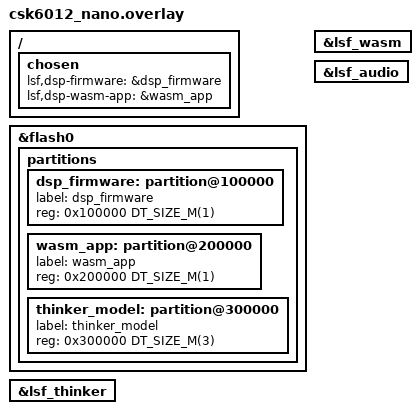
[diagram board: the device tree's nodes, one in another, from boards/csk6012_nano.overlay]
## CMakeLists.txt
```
# Copyright (c) 2023 LISTENAI
# SPDX-License-Identifier: Apache-2.0

cmake_minimum_required(VERSION 3.20.0)

find_package(Zephyr REQUIRED HINTS $ENV{ZEPHYR_BASE})
project(thinker_wasm_test)

target_sources(app PRIVATE src/main.c)
```

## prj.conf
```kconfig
CONFIG_HEAP_MEM_POOL_SIZE=204800

CONFIG_CSK_HEAP=y
CONFIG_CSK_HEAP_MEM_POOL_SIZE=40960
CONFIG_ZTEST=y

CONFIG_CSK6_FLASH_STALL_SECOND_CORE=n
```

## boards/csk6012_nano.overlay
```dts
/*
 * Copyright(c) 2023 LISTENAI
 * SPDX-License-Identifier: Apache-2.0
 */

#include <lsf/lsf.dtsi>

/ {
	chosen {
		lsf,dsp-firmware = &dsp_firmware;
		lsf,dsp-wasm-app = &wasm_app;
	};
};

&flash0 {
	partitions {
		dsp_firmware: partition@100000 {
			label = "dsp_firmware";
			reg = <0x100000 DT_SIZE_M(1)>;
		};

		wasm_app: partition@200000 {
			label = "wasm_app";
			reg = <0x200000 DT_SIZE_M(1)>;
		};

		thinker_model: partition@300000 {
			label = "thinker_model";
			reg = <0x300000 DT_SIZE_M(3)>;
		};
	};
};

&lsf_thinker {
	status = "okay";
};

&lsf_wasm {
	status = "okay";
};

&lsf_audio {
	status = "okay";
};
```

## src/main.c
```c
#include <zephyr/kernel.h>
#include <zephyr/device.h>

#include "AudioSystem.h"
#include "AudioTrack.h"
#include "AudioRecord.h"

#include <stdint.h>
#include <string.h>
#include <zephyr/storage/flash_map.h>
#include <ztest.h>

#include <lsf/services/thinker.h>

#include "apple_input.h"


#define SAMPLE_RATE (16000)
#define CHANNEL_CNT (1)

#define RECORD_SECS       (5)
#define RECORD_SAMPLE_CNT (SAMPLE_RATE * RECORD_SECS)

static AudioRecord s_record_obj;
static AudioTrack s_track_obj;

__attribute__((section(".psram_section"))) static uint8_t
	recording[sizeof(uint16_t) * RECORD_SAMPLE_CNT * CHANNEL_CNT];

#define FLASH_ADDR         (DT_REG_ADDR(DT_CHOSEN(zephyr_flash)))
#define THINKER_MODEL_ADDR (FLASH_ADDR + FLASH_AREA_OFFSET(thinker_model))

const char *classes[] = {
	"apple",       "aquarium_fish", "baby",      "bear",       "beaver",       "bed",
	"bee",         "beetle",        "bicycle",   "bottle",     "bowl",         "boy",
	"bridge",      "bus",           "butterfly", "camel",      "can",          "castle",
	"caterpillar", "cattle",        "chair",     "chimpanzee", "clock",        "cloud",
	"cockroach",   "couch",         "crab",      "crocodile",  "cup",          "dinosaur",
	"dolphin",     "elephant",      "flatfish",  "forest",     "fox",          "girl",
	"hamster",     "house",         "kangaroo",  "keyboard",   "lamp",         "lawn_mower",
	"leopard",     "lion",          "lizard",    "lobster",    "man",          "maple_tree",
	"motorcycle",  "mountain",      "mouse",     "mushroom",   "oak_tree",     "orange",
	"orchid",      "otter",         "palm_tree", "pear",       "pickup_truck", "pine_tree",
	"plain",       "plate",         "poppy",     "porcupine",  "possum",       "rabbit",
	"raccoon",     "ray",           "road",      "rocket",     "rose",         "sea",
	"seal",        "shark",         "shrew",     "skunk",      "skyscraper",   "snail",
	"snake",       "spider",        "squirrel",  "streetcar",  "sunflower",    "sweet_pepper",
	"table",       "tank",          "telephone", "television", "tiger",        "tractor",
	"train",       "trout",         "tulip",     "turtle",     "wardrobe",     "whale",
	"willow_tree", "wolf",          "woman",     "worm"};

static void test_thinker()
{
	/* 加载 Thinker 模型，注意传入模型的实际字节数 */
	lsf_thinker_set_model((const void *)THINKER_MODEL_ADDR, 2932416);
	printk("Model loaded\n");

	int8_t *output;
	uint32_t output_size;

	printk("setInput, size: %d\n", input_resource_len);
	lsf_thinker_set_input(input_resource, input_resource_len);

	lsf_thinker_get_output((void **)&output, &output_size);
	printk("getOutput, size: %d\n", output_size);

	int predicted_category_index = 0;
	int8_t max_probability = output[0];
	for (int idx = 1; idx < output_size; idx++) {
		if (output[idx] > max_probability) {
			max_probability = output[idx];
			predicted_category_index = idx;
		}
	}

	printk("Max probability: %d, index: %d\n", max_probability,
			predicted_category_index);
	printk("Predicted label: %s\n", classes[predicted_category_index]);

	zassert_equal(strcmp(classes[predicted_category_index], "apple"), 0, "Failed to predict apple");

}

static void test_record_and_track_thinker()
{
	int ret;
	AudioTrack *track = &s_track_obj;
	AudioRecord *record = &s_record_obj;
	
	ret = AudioRecord_ctor(record, 0, SAMPLE_RATE, PCM_16_BIT, CHANNEL_IN_LEFT, 160, NULL);

	ret = AudioTrack_ctor(track, SAMPLE_RATE, PCM_16_BIT, CHANNEL_OUT_MONO, 160, NULL);
	zassert_equal(ret, NO_ERROR, "Failed to create AudioTrack object");

	AudioRecord_start(record);
	
	ret = AudioRecord_read(record, recording,
					sizeof(uint16_t) * RECORD_SAMPLE_CNT * CHANNEL_CNT);

	AudioRecord_stop(record);

	AudioTrack_start(track);
	ret = AudioTrack_write(track, recording,
					sizeof(uint16_t) * RECORD_SAMPLE_CNT * CHANNEL_CNT);
	zassert_equal(ret, sizeof(uint16_t) * RECORD_SAMPLE_CNT * CHANNEL_CNT, "Failed to write audio track");

	AudioTrack_stop(track);
	lsf_thinker_set_model((const void *)THINKER_MODEL_ADDR, 2932416);
	printk("Model loaded\n");

	int8_t *output;
	uint32_t output_size;

	printk("setInput, size: %d\n", input_resource_len);
	lsf_thinker_set_input(input_resource, input_resource_len);

	lsf_thinker_get_output((void **)&output, &output_size);
	printk("getOutput, size: %d\n", output_size);

	int predicted_category_index = 0;
	int8_t max_probability = output[0];
	for (int idx = 1; idx < output_size; idx++) {
		if (output[idx] > max_probability) {
			max_probability = output[idx];
			predicted_category_index = idx;
		}
	}

	printk("Max probability: %d, index: %d\n", max_probability,
			predicted_category_index);
	printk("Predicted label: %s\n", classes[predicted_category_index]);

	zassert_equal(strcmp(classes[predicted_category_index], "apple"), 0, "Failed to predict apple");

	ret = AudioTrack_dtor(track);
	ret = AudioRecord_dtor(record);
}

static void test_thinker_set_model_0()
{
	/* 加载 Thinker 模型，注意传入模型的实际字节数 */
	lsf_thinker_set_model((const void *)THINKER_MODEL_ADDR, 0);
	printk("Model loaded\n");

	int8_t *output;
	uint32_t output_size;

	printk("setInput, size: %d\n", input_resource_len);
	lsf_thinker_set_input(input_resource, input_resource_len);

	lsf_thinker_get_output((void **)&output, &output_size);
	printk("getOutput, size: %d\n", output_size);

	int predicted_category_index = 0;
	int8_t max_probability = output[0];
	for (int idx = 1; idx < output_size; idx++) {
		if (output[idx] > max_probability) {
			max_probability = output[idx];
			predicted_category_index = idx;
		}
	}

	printk("Max probability: %d, index: %d\n", max_probability,
			predicted_category_index);
	printk("Predicted label: %s\n", classes[predicted_category_index]);
	zassert_equal(strcmp(classes[predicted_category_index], "apple"), 0, "Failed to predict apple");

}

static void test_thinker_set_input_size_0()
{
	/* 加载 Thinker 模型，注意传入模型的实际字节数 */
	lsf_thinker_set_model((const void *)THINKER_MODEL_ADDR, 2932416);
	printk("Model loaded\n");

	int8_t *output;
	uint32_t output_size;

	printk("setInput, size: %d\n", 0);
	lsf_thinker_set_input(input_resource, 0);

	lsf_thinker_get_output((void **)&output, &output_size);
	printk("getOutput, size: %d\n", output_size);

	int predicted_category_index = 0;
	int8_t max_probability = output[0];
	for (int idx = 1; idx < output_size; idx++) {
		if (output[idx] > max_probability) {
			max_probability = output[idx];
			predicted_category_index = idx;
		}
	}

	printk("Max probability: %d, index: %d\n", max_probability,
			predicted_category_index);
	printk("Predicted label: %s\n", classes[predicted_category_index]);
	zassert_equal(strcmp(classes[predicted_category_index], "apple"), 0, "Failed to predict apple");

}

static void test_record_and_track_thinker_100_times()
{
	int ret;
	AudioTrack *track = &s_track_obj;
	AudioRecord *record = &s_record_obj;
	
	ret = AudioRecord_ctor(record, 0, SAMPLE_RATE, PCM_16_BIT, CHANNEL_IN_LEFT, 160, NULL);

	ret = AudioTrack_ctor(track, SAMPLE_RATE, PCM_16_BIT, CHANNEL_OUT_MONO, 160, NULL);
	zassert_equal(ret, NO_ERROR, "Failed to create AudioTrack object");

	AudioRecord_start(record);
	
	ret = AudioRecord_read(record, recording,
					sizeof(uint16_t) * RECORD_SAMPLE_CNT * CHANNEL_CNT);

	AudioRecord_stop(record);
	AudioTrack_start(track);
	ret = AudioTrack_write(track, recording,
					sizeof(uint16_t) * RECORD_SAMPLE_CNT * CHANNEL_CNT);
	zassert_equal(ret, sizeof(uint16_t) * RECORD_SAMPLE_CNT * CHANNEL_CNT, "Failed to write audio track");

	AudioTrack_stop(track);
	lsf_thinker_set_model((const void *)THINKER_MODEL_ADDR, 2932416);
	printk("Model loaded\n");

	int8_t *output;
	uint32_t output_size;

	for (int i=1;i<100;i++)
	{
		printk("count:%d\n", i);
		printk("setInput, size: %d\n", input_resource_len);
		lsf_thinker_set_input(input_resource, input_resource_len);

		lsf_thinker_get_output((void **)&output, &output_size);
		printk("getOutput, size: %d\n", output_size);

		int predicted_category_index = 0;
		int8_t max_probability = output[0];
		for (int idx = 1; idx < output_size; idx++) {
			if (output[idx] > max_probability) {
				max_probability = output[idx];
				predicted_category_index = idx;
			}
		}

		printk("Max probability: %d, index: %d\n", max_probability,
				predicted_category_index);
		printk("Predicted label: %s\n", classes[predicted_category_index]);

		zassert_equal(strcmp(classes[predicted_category_index], "apple"), 0, "Failed to predict apple");
	}

	ret = AudioTrack_dtor(track);
	ret = AudioRecord_dtor(record);
}

void test_main(void)
{
	ztest_test_suite(thinker_wasm_test,
					ztest_unit_test(test_thinker),
					ztest_unit_test(test_record_and_track_thinker),
					ztest_unit_test(test_thinker_set_model_0),
					ztest_unit_test(test_thinker_set_input_size_0),
					ztest_unit_test(test_record_and_track_thinker_100_times));
	ztest_run_test_suite(thinker_wasm_test);
}
```

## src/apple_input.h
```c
#pragma once

const int input_resource_len = 3072;
__attribute__((section(".rodata")))
const char input_resource[3072] = {
	0x74, 0x74, 0x74, 0x74, 0x74, 0x74, 0x74, 0x74, 0x74, 0x74, 0x74, 0x74, 0x74, 0x74, 0x74, 0x74, 
	0x74, 0x74, 0x74, 0x74, 0x74, 0x74, 0x74, 0x74, 0x74, 0x74, 0x74, 0x74, 0x74, 0x74, 0x74, 0x74, 
	0x74, 0x74, 0x74, 0x74, 0x74, 0x74, 0x74, 0x74, 0x74, 0x74, 0x74, 0x74, 0x74, 0x74, 0x74, 0x74, 
	0x74, 0x74, 0x74, 0x74, 0x74, 0x74, 0x74, 0x74, 0x74, 0x74, 0x74, 0x74, 0x74, 0x74, 0x74, 0x74, 
	0x74, 0x74, 0x74, 0x74, 0x74, 0x74, 0x74, 0x74, 0x74, 0x74, 0x74, 0x6d, 0x65, 0x69, 0x71, 0x74, 
	0x74, 0x74, 0x74, 0x74, 0x74, 0x74, 0x74, 0x74, 0x74, 0x74, 0x74, 0x74, 0x74, 0x74, 0x74, 0x74, 
	0x74, 0x74, 0x74, 0x74, 0x74, 0x74, 0x74, 0x74, 0x74, 0x74, 0x60, 0x31, 0x27, 0x2a, 0x3e, 0x67, 
	0x74, 0x74, 0x74, 0x74, 0x74, 0x74, 0x74, 0x74, 0x74, 0x74, 0x74, 0x74, 0x74, 0x74, 0x74, 0x74, 
	0x74, 0x74, 0x74, 0x74, 0x74, 0x74, 0x74, 0x74, 0x74, 0x70, 0x38, 0x18, 0x1b, 0x21, 0x14, 0x26, 
	0x5f, 0x74, 0x74, 0x74, 0x74, 0x74, 0x74, 0x74, 0x74, 0x74, 0x74, 0x74, 0x74, 0x74, 0x74, 0x74, 
	0x74, 0x74, 0x74, 0x74, 0x74, 0x74, 0x74, 0x74, 0x74, 0x6f, 0x31, 0x1e, 0x21, 0x26, 0x20, 0xf, 
	0x1e, 0x6b, 0x74, 0x74, 0x74, 0x74, 0x74, 0x74, 0x74, 0x74, 0x74, 0x74, 0x74, 0x74, 0x74, 0x74, 
	0x74, 0x74, 0x74, 0x74, 0x74, 0x74, 0x74, 0x74, 0x74, 0x74, 0x66, 0x3d, 0x29, 0x27, 0x31, 0x35, 
	0x27, 0x27, 0x69, 0x74, 0x74, 0x74, 0x74, 0x74, 0x74, 0x74, 0x74, 0x74, 0x74, 0x74, 0x74, 0x74, 
	0x74, 0x74, 0x74, 0x74, 0x74, 0x74, 0x74, 0x74, 0x74, 0x74, 0x74, 0x72, 0x6b, 0x69, 0x6e, 0x72, 
	0x6b, 0x25, 0x6c, 0x74, 0x74, 0x74, 0x74, 0x74, 0x74, 0x74, 0x74, 0x74, 0x74, 0x74, 0x74, 0x74, 
	0x74, 0x74, 0x74, 0x74, 0x74, 0x74, 0x74, 0x74, 0x74, 0x74, 0x73, 0x73, 0x6e, 0x6b, 0x6a, 0x68, 
	0x5f, 0x40, 0x6e, 0x73, 0x74, 0x74, 0x74, 0x74, 0x74, 0x74, 0x74, 0x74, 0x74, 0x74, 0x74, 0x74, 
	0x74, 0x74, 0x74, 0x74, 0x74, 0x74, 0x74, 0x74, 0x72, 0x70, 0x6f, 0x6d, 0x6a, 0x66, 0x5d, 0x56, 
	0x4e, 0x45, 0x5f, 0x6a, 0x72, 0x73, 0x74, 0x74, 0x74, 0x74, 0x74, 0x74, 0x74, 0x74, 0x74, 0x74, 
	0x74, 0x74, 0x74, 0x74, 0x74, 0x74, 0x74, 0x6e, 0x68, 0x69, 0x66, 0x60, 0x5d, 0x62, 0x5d, 0x50, 
	0x39, 0x41, 0x56, 0x5f, 0x62, 0x66, 0x6b, 0x71, 0x74, 0x74, 0x74, 0x74, 0x74, 0x74, 0x74, 0x74, 
	0x74, 0x74, 0x74, 0x74, 0x74, 0x74, 0x6e, 0x61, 0x5f, 0x5e, 0x59, 0x52, 0x4e, 0x50, 0x55, 0x52, 
	0x46, 0x45, 0x50, 0x59, 0x58, 0x5c, 0x5f, 0x64, 0x70, 0x74, 0x74, 0x74, 0x74, 0x74, 0x74, 0x74, 
	0x74, 0x74, 0x74, 0x74, 0x74, 0x72, 0x5f, 0x52, 0x52, 0x56, 0x59, 0x4d, 0x4a, 0x4a, 0x50, 0x51, 
	0x4e, 0x4f, 0x53, 0x52, 0x55, 0x56, 0x5a, 0x5f, 0x63, 0x70, 0x74, 0x74, 0x74, 0x74, 0x74, 0x74, 
	0x74, 0x74, 0x74, 0x74, 0x74, 0x69, 0x4c, 0x44, 0x45, 0x4a, 0x4c, 0x48, 0x49, 0x4e, 0x52, 0x52, 
	0x51, 0x50, 0x4f, 0x52, 0x59, 0x58, 0x54, 0x59, 0x5e, 0x66, 0x73, 0x74, 0x74, 0x74, 0x74, 0x74, 
	0x74, 0x74, 0x74, 0x74, 0x74, 0x57, 0x3a, 0x37, 0x37, 0x3d, 0x42, 0x43, 0x47, 0x50, 0x56, 0x52, 
	0x4f, 0x4c, 0x47, 0x56, 0x5e, 0x59, 0x54, 0x53, 0x58, 0x5a, 0x6e, 0x74, 0x74, 0x74, 0x74, 0x74, 
	0x74, 0x74, 0x74, 0x74, 0x71, 0x44, 0x2b, 0x2c, 0x30, 0x2f, 0x37, 0x40, 0x49, 0x52, 0x4e, 0x47, 
	0x45, 0x41, 0x40, 0x5a, 0x61, 0x59, 0x54, 0x50, 0x54, 0x55, 0x65, 0x74, 0x74, 0x74, 0x74, 0x74, 
	0x74, 0x74, 0x74, 0x74, 0x6e, 0x35, 0x1d, 0x22, 0x2e, 0x29, 0x2e, 0x3e, 0x4a, 0x46, 0x3b, 0x36, 
	0x3a, 0x38, 0x37, 0x54, 0x60, 0x58, 0x54, 0x4e, 0x50, 0x50, 0x5d, 0x74, 0x74, 0x74, 0x74, 0x74, 
	0x74, 0x74, 0x74, 0x74, 0x68, 0x2a, 0x12, 0x16, 0x1b, 0x22, 0x24, 0x31, 0x3a, 0x32, 0x2f, 0x29, 
	0x2a, 0x2c, 0x2f, 0x4b, 0x5c, 0x57, 0x53, 0x4e, 0x4b, 0x4c, 0x5a, 0x74, 0x74, 0x74, 0x74, 0x74, 
	0x74, 0x74, 0x74, 0x74, 0x6a, 0x2a, 0xc, 0xc, 0xf, 0x16, 0x20, 0x26, 0x2f, 0x2b, 0x22, 0x20, 
	0x27, 0x26, 0x28, 0x3c, 0x52, 0x51, 0x50, 0x4c, 0x47, 0x44, 0x5d, 0x74, 0x74, 0x74, 0x74, 0x74, 
	0x74, 0x74, 0x74, 0x74, 0x70, 0x33, 0xa, 0x6, 0x10, 0x11, 0x17, 0x1c, 0x25, 0x22, 0x1e, 0x1c, 
	0x19, 0x1e, 0x21, 0x31, 0x3f, 0x42, 0x46, 0x45, 0x43, 0x42, 0x63, 0x74, 0x74, 0x74, 0x74, 0x74, 
	0x74, 0x74, 0x74, 0x75, 0x72, 0x43, 0x11, 0x6, 0x7, 0xa, 0xc, 0x10, 0x15, 0x18, 0x18, 0x17, 
	0x18, 0x1a, 0x1f, 0x2a, 0x31, 0x34, 0x3d, 0x3a, 0x3e, 0x49, 0x69, 0x74, 0x74, 0x74, 0x74, 0x74, 
	0x74, 0x74, 0x74, 0x74, 0x74, 0x57, 0x15, 0x3, 0xff, 0x6, 0x7, 0x9, 0xb, 0x12, 0x15, 0x11, 
	0x13, 0x15, 0x18, 0x22, 0x28, 0x31, 0x33, 0x31, 0x3b, 0x4c, 0x6f, 0x74, 0x74, 0x74, 0x74, 0x74, 
	0x74, 0x74, 0x74, 0x74, 0x73, 0x66, 0x24, 0x2, 0xf9, 0x2, 0x3, 0x2, 0x4, 0x8, 0xc, 0xb, 
	0xd, 0x10, 0x18, 0x1e, 0x22, 0x26, 0x29, 0x2c, 0x3a, 0x58, 0x73, 0x74, 0x74, 0x74, 0x74, 0x74, 
	0x74, 0x74, 0x74, 0x74, 0x72, 0x6f, 0x3a, 0x4, 0xf8, 0xfa, 0xfe, 0xfd, 0xfd, 0x1, 0x5, 0x8, 
	0x6, 0xa, 0x13, 0x15, 0x19, 0x1d, 0x22, 0x26, 0x40, 0x68, 0x74, 0x74, 0x74, 0x74, 0x74, 0x74, 
	0x74, 0x74, 0x74, 0x74, 0x72, 0x71, 0x58, 0xe, 0xfa, 0xf7, 0xfa, 0xf7, 0xf9, 0xf8, 0xfc, 0xff, 
	0x1, 0x5, 0xd, 0x10, 0x12, 0x15, 0x18, 0x28, 0x56, 0x72, 0x74, 0x74, 0x74, 0x74, 0x74, 0x74, 
	0x74, 0x74, 0x74, 0x75, 0x74, 0x73, 0x6e, 0x2b, 0xf9, 0xf8, 0xf6, 0xf3, 0xf2, 0xf5, 0xf8, 0xf8, 
	0xfa, 0x2, 0x4, 0x7, 0xf, 0xa, 0x15, 0x3e, 0x6d, 0x74, 0x74, 0x74, 0x74, 0x74, 0x74, 0x74, 
	0x74, 0x74, 0x74, 0x74, 0x74, 0x74, 0x74, 0x5a, 0x4, 0xef, 0xf4, 0xef, 0xec, 0xef, 0xf4, 0xf4, 
	0xf3, 0xf5, 0xf9, 0x2, 0x3, 0x0, 0x25, 0x62, 0x74, 0x74, 0x74, 0x74, 0x74, 0x74, 0x74, 0x74, 
	0x74, 0x74, 0x74, 0x74, 0x74, 0x74, 0x74, 0x6f, 0x3d, 0xf4, 0xe9, 0xe6, 0xe4, 0xe6, 0xea, 0xeb, 
	0xee, 0xee, 0xf4, 0xfb, 0xf9, 0xf, 0x51, 0x6e, 0x72, 0x74, 0x74, 0x74, 0x74, 0x74, 0x74, 0x74, 
	0x74, 0x74, 0x74, 0x74, 0x74, 0x74, 0x70, 0x68, 0x61, 0x32, 0xf2, 0xdf, 0xdb, 0xdb, 0xdd, 0xe1, 
	0xe3, 0xe5, 0xec, 0xf3, 0x6, 0x42, 0x62, 0x67, 0x6e, 0x74, 0x75, 0x74, 0x74, 0x74, 0x74, 0x74, 
	0x74, 0x74, 0x74, 0x74, 0x72, 0x6f, 0x69, 0x62, 0x5b, 0x4c, 0x1b, 0xde, 0xc9, 0xc6, 0xcb, 0xd1, 
	0xd5, 0xdc, 0xe5, 0xfb, 0x2a, 0x4c, 0x5c, 0x65, 0x6e, 0x73, 0x74, 0x74, 0x74, 0x74, 0x74, 0x74, 
	0x74, 0x74, 0x74, 0x75, 0x73, 0x70, 0x6d, 0x6a, 0x63, 0x55, 0x3e, 0x26, 0x19, 0x12, 0x12, 0x14, 
	0x1c, 0x25, 0x33, 0x40, 0x4c, 0x58, 0x62, 0x6b, 0x71, 0x74, 0x74, 0x74, 0x74, 0x74, 0x74, 0x74, 
	0x74, 0x74, 0x74, 0x74, 0x74, 0x74, 0x74, 0x73, 0x71, 0x6d, 0x66, 0x62, 0x60, 0x5f, 0x5f, 0x5f, 
	0x60, 0x62, 0x63, 0x66, 0x68, 0x6c, 0x6f, 0x73, 0x74, 0x74, 0x74, 0x74, 0x74, 0x74, 0x74, 0x74, 
	0x7e, 0x7e, 0x7e, 0x7e, 0x7e, 0x7e, 0x7e, 0x7e, 0x7e, 0x7e, 0x7e, 0x7e, 0x7e, 0x7e, 0x7e, 0x7e, 
	0x7e, 0x7e, 0x7e, 0x7e, 0x7e, 0x7e, 0x7e, 0x7e, 0x7e, 0x7e, 0x7e, 0x7e, 0x7e, 0x7e, 0x7e, 0x7e, 
	0x7e, 0x7e, 0x7e, 0x7e, 0x7e, 0x7e, 0x7e, 0x7e, 0x7e, 0x7e, 0x7e, 0x7e, 0x7e, 0x7e, 0x7e, 0x7e, 
	0x7e, 0x7e, 0x7e, 0x7e, 0x7e, 0x7e, 0x7e, 0x7e, 0x7e, 0x7e, 0x7e, 0x7e, 0x7e, 0x7e, 0x7e, 0x7e, 
	0x7e, 0x7e, 0x7e, 0x7e, 0x7e, 0x7e, 0x7e, 0x7e, 0x7e, 0x7e, 0x7e, 0x78, 0x72, 0x75, 0x7c, 0x7e, 
	0x7e, 0x7e, 0x7e, 0x7e, 0x7e, 0x7e, 0x7e, 0x7e, 0x7e, 0x7e, 0x7e, 0x7e, 0x7e, 0x7e, 0x7e, 0x7e, 
	0x7e, 0x7e, 0x7e, 0x7e, 0x7e, 0x7e, 0x7e, 0x7e, 0x7e, 0x7e, 0x6e, 0x45, 0x41, 0x44, 0x53, 0x73, 
	0x7e, 0x7e, 0x7e, 0x7e, 0x7e, 0x7e, 0x7e, 0x7e, 0x7e, 0x7e, 0x7e, 0x7e, 0x7e, 0x7e, 0x7e, 0x7e, 
	0x7e, 0x7e, 0x7e, 0x7e, 0x7e, 0x7e, 0x7e, 0x7e, 0x7e, 0x7a, 0x4a, 0x30, 0x35, 0x3a, 0x2e, 0x3b, 
	0x6c, 0x7e, 0x7e, 0x7e, 0x7e, 0x7e, 0x7e, 0x7e, 0x7e, 0x7e, 0x7e, 0x7e, 0x7e, 0x7e, 0x7e, 0x7e, 
	0x7e, 0x7e, 0x7e, 0x7e, 0x7e, 0x7e, 0x7e, 0x7e, 0x7e, 0x79, 0x42, 0x35, 0x39, 0x40, 0x3a, 0x27, 
	0x2f, 0x75, 0x7e, 0x7e, 0x7e, 0x7e, 0x7e, 0x7e, 0x7e, 0x7e, 0x7e, 0x7e, 0x7e, 0x7e, 0x7e, 0x7e, 
	0x7e, 0x7e, 0x7e, 0x7e, 0x7e, 0x7e, 0x7e, 0x7e, 0x7e, 0x7e, 0x71, 0x4c, 0x3f, 0x3e, 0x46, 0x49, 
	0x36, 0x23, 0x70, 0x7e, 0x7e, 0x7e, 0x7e, 0x7e, 0x7e, 0x7e, 0x7e, 0x7e, 0x7e, 0x7e, 0x7e, 0x7e, 
	0x7e, 0x7e, 0x7e, 0x7e, 0x7e, 0x7e, 0x7e, 0x7e, 0x7e, 0x7e, 0x7e, 0x7d, 0x75, 0x73, 0x78, 0x7c, 
	0x73, 0x19, 0x73, 0x7e, 0x7e, 0x7e, 0x7e, 0x7e, 0x7e, 0x7e, 0x7e, 0x7e, 0x7e, 0x7e, 0x7e, 0x7e, 
	0x7e, 0x7e, 0x7e, 0x7e, 0x7e, 0x7e, 0x7e, 0x7e, 0x7e, 0x7e, 0x7c, 0x7b, 0x74, 0x6a, 0x64, 0x5e, 
	0x54, 0x2a, 0x6f, 0x7b, 0x7e, 0x7e, 0x7e, 0x7e, 0x7e, 0x7e, 0x7e, 0x7e, 0x7e, 0x7e, 0x7e, 0x7e, 
	0x7e, 0x7e, 0x7e, 0x7e, 0x7e, 0x7e, 0x7e, 0x7d, 0x79, 0x74, 0x70, 0x67, 0x61, 0x55, 0x3f, 0x2c, 
	0x1b, 0x11, 0x39, 0x5b, 0x76, 0x7c, 0x7d, 0x7e, 0x7e, 0x7e, 0x7e, 0x7e, 0x7e, 0x7e, 0x7e, 0x7e, 
	0x7e, 0x7e, 0x7e, 0x7e, 0x7e, 0x7e, 0x7d, 0x6e, 0x61, 0x5c, 0x4a, 0x3a, 0x33, 0x44, 0x3e, 0x28, 
	0xff, 0x3, 0x23, 0x3f, 0x4d, 0x54, 0x63, 0x77, 0x7e, 0x7e, 0x7e, 0x7e, 0x7e, 0x7e, 0x7e, 0x7e, 
	0x7e, 0x7e, 0x7e, 0x7e, 0x7e, 0x7e, 0x70, 0x47, 0x39, 0x33, 0x1d, 0x1, 0xf1, 0xfd, 0xb, 0x18, 
	0x16, 0x12, 0x27, 0x33, 0x29, 0x27, 0x33, 0x4d, 0x71, 0x7e, 0x7e, 0x7e, 0x7e, 0x7e, 0x7e, 0x7e, 
	0x7e, 0x7e, 0x7e, 0x7e, 0x7e, 0x7a, 0x48, 0x15, 0xd, 0x1c, 0x23, 0xf2, 0xdc, 0xd7, 0xe6, 0xfa, 
	0x3, 0x4, 0x13, 0x14, 0x1b, 0x19, 0x23, 0x30, 0x47, 0x73, 0x7e, 0x7e, 0x7e, 0x7e, 0x7e, 0x7e, 
	0x7e, 0x7e, 0x7e, 0x7e, 0x7e, 0x67, 0x15, 0xf1, 0xee, 0xf6, 0xfc, 0xe8, 0xdd, 0xde, 0xee, 0xfc, 
	0xf8, 0xf6, 0xf9, 0x4, 0x20, 0x1c, 0x14, 0x1a, 0x2d, 0x51, 0x7b, 0x7e, 0x7e, 0x7e, 0x7e, 0x7e, 
	0x7e, 0x7e, 0x7e, 0x7e, 0x7d, 0x45, 0xf1, 0xdd, 0xd5, 0xd2, 0xd5, 0xd3, 0xd3, 0xe5, 0xfd, 0xfc, 
	0xed, 0xe9, 0xe6, 0x8, 0x2e, 0x1b, 0x9, 0x5, 0x1a, 0x2f, 0x6d, 0x7e, 0x7e, 0x7e, 0x7e, 0x7e, 
	0x7e, 0x7e, 0x7e, 0x7e, 0x79, 0x25, 0xdb, 0xc9, 0xc3, 0xbe, 0xc3, 0xc9, 0xda, 0xf7, 0xf0, 0xe0, 
	0xdc, 0xd9, 0xd9, 0x14, 0x36, 0x1a, 0x0, 0xf5, 0xa, 0x1a, 0x55, 0x7e, 0x7e, 0x7e, 0x7e, 0x7e, 
	0x7e, 0x7e, 0x7e, 0x7e, 0x74, 0xe, 0xcc, 0xbf, 0xbc, 0xb8, 0xb8, 0xc9, 0xe9, 0xe2, 0xc7, 0xbe, 
	0xc7, 0xc9, 0xca, 0xd, 0x30, 0xd, 0xf9, 0xf0, 0xff, 0xd, 0x42, 0x7d, 0x7e, 0x7e, 0x7e, 0x7e, 
	0x7e, 0x7e, 0x7e, 0x7e, 0x6c, 0xff, 0xc4, 0xb6, 0xb0, 0xb5, 0xb5, 0xc2, 0xd4, 0xc1, 0xb3, 0xac, 
	0xb2, 0xba, 0xbc, 0xf1, 0x16, 0x0, 0xf9, 0xf0, 0xf5, 0x0, 0x3c, 0x7d, 0x7e, 0x7e, 0x7e, 0x7e, 
	0x7e, 0x7e, 0x7e, 0x7e, 0x6e, 0x5, 0xc4, 0xb3, 0xaf, 0xb7, 0xbe, 0xc3, 0xcb, 0xc0, 0xae, 0xa9, 
	0xaf, 0xb3, 0xb0, 0xca, 0xf1, 0xf4, 0xf3, 0xed, 0xec, 0xf7, 0x44, 0x7d, 0x7e, 0x7e, 0x7e, 0x7e, 
	0x7e, 0x7e, 0x7e, 0x7e, 0x79, 0x1d, 0xce, 0xba, 0xba, 0xbb, 0xc0, 0xc2, 0xc6, 0xbe, 0xb5, 0xaf, 
	0xaa, 0xaa, 0xab, 0xba, 0xcc, 0xda, 0xe5, 0xe3, 0xe6, 0x0, 0x58, 0x7e, 0x7e, 0x7e, 0x7e, 0x7e, 
	0x7e, 0x7e, 0x7e, 0x7d, 0x7c, 0x38, 0xdf, 0xc7, 0xbf, 0xbb, 0xba, 0xbe, 0xbf, 0xbd, 0xb8, 0xb5, 
	0xb4, 0xb0, 0xb4, 0xba, 0xbf, 0xc9, 0xd9, 0xda, 0xec, 0x1b, 0x68, 0x7e, 0x7e, 0x7e, 0x7e, 0x7e, 
	0x7e, 0x7e, 0x7e, 0x7d, 0x7c, 0x54, 0xe9, 0xc9, 0xc0, 0xbc, 0xba, 0xbd, 0xbc, 0xbd, 0xbb, 0xb8, 
	0xb6, 0xb4, 0xb7, 0xbb, 0xc1, 0xca, 0xd1, 0xd7, 0xf7, 0x2c, 0x74, 0x7e, 0x7e, 0x7e, 0x7e, 0x7e, 
	0x7e, 0x7e, 0x7e, 0x7d, 0x7d, 0x6c, 0x9, 0xd3, 0xc3, 0xbf, 0xbe, 0xbc, 0xba, 0xba, 0xb9, 0xb8, 
	0xb8, 0xb6, 0xb8, 0xbb, 0xbf, 0xc4, 0xcb, 0xd4, 0x0, 0x49, 0x7c, 0x7e, 0x7e, 0x7e, 0x7e, 0x7e, 
	0x7e, 0x7e, 0x7e, 0x7c, 0x7c, 0x79, 0x2c, 0xdb, 0xc3, 0xbb, 0xba, 0xb9, 0xb7, 0xb7, 0xb8, 0xb8, 
	0xb5, 0xb6, 0xb6, 0xb9, 0xbd, 0xc1, 0xc8, 0xd7, 0x1b, 0x6a, 0x7e, 0x7e, 0x7e, 0x7e, 0x7e, 0x7e, 
	0x7e, 0x7e, 0x7e, 0x7d, 0x7d, 0x7c, 0x58, 0xec, 0xc5, 0xbb, 0xb8, 0xb6, 0xb6, 0xb5, 0xb6, 0xb5, 
	0xb3, 0xb3, 0xb4, 0xb7, 0xba, 0xc0, 0xc9, 0xef, 0x48, 0x7b, 0x7e, 0x7e, 0x7e, 0x7e, 0x7e, 0x7e, 
	0x7e, 0x7e, 0x7e, 0x7d, 0x7c, 0x7c, 0x75, 0x18, 0xcb, 0xbc, 0xb8, 0xb5, 0xb3, 0xb3, 0xb1, 0xb2, 
	0xb1, 0xb1, 0xb2, 0xb6, 0xbc, 0xc1, 0xd6, 0x24, 0x71, 0x7e, 0x7e, 0x7e, 0x7e, 0x7e, 0x7e, 0x7e, 
	0x7e, 0x7e, 0x7e, 0x7d, 0x7d, 0x7d, 0x7d, 0x59, 0xe7, 0xbd, 0xb8, 0xb3, 0xb2, 0xb0, 0xad, 0xad, 
	0xac, 0xad, 0xb0, 0xb7, 0xbf, 0xc7, 0xff, 0x61, 0x7d, 0x7e, 0x7e, 0x7e, 0x7e, 0x7e, 0x7e, 0x7e, 
	0x7e, 0x7e, 0x7e, 0x7e, 0x7e, 0x7e, 0x7b, 0x75, 0x35, 0xd2, 0xb8, 0xb3, 0xaf, 0xac, 0xa9, 0xa6, 
	0xa8, 0xaa, 0xae, 0xb5, 0xbc, 0xe5, 0x49, 0x75, 0x7a, 0x7e, 0x7e, 0x7e, 0x7e, 0x7e, 0x7e, 0x7e, 
	0x7e, 0x7e, 0x7e, 0x7e, 0x7d, 0x7c, 0x75, 0x6e, 0x66, 0x28, 0xd0, 0xb3, 0xad, 0xa9, 0xa7, 0xa4, 
	0xa5, 0xaa, 0xaf, 0xb8, 0xe0, 0x39, 0x67, 0x6d, 0x74, 0x7b, 0x7d, 0x7e, 0x7e, 0x7e, 0x7e, 0x7e, 
	0x7e, 0x7e, 0x7e, 0x7c, 0x79, 0x74, 0x6e, 0x67, 0x60, 0x4e, 0x13, 0xc9, 0xb4, 0xb0, 0xb0, 0xb0, 
	0xb3, 0xba, 0xc8, 0xe6, 0x21, 0x4e, 0x60, 0x6a, 0x73, 0x7a, 0x7c, 0x7e, 0x7e, 0x7e, 0x7e, 0x7e, 
	0x7e, 0x7e, 0x7e, 0x7d, 0x79, 0x75, 0x71, 0x6f, 0x68, 0x59, 0x3f, 0x24, 0x16, 0x10, 0xf, 0x12, 
	0x19, 0x24, 0x33, 0x42, 0x4e, 0x5c, 0x67, 0x70, 0x77, 0x7c, 0x7d, 0x7e, 0x7e, 0x7e, 0x7e, 0x7e, 
	0x7e, 0x7e, 0x7e, 0x7e, 0x7d, 0x7c, 0x7b, 0x78, 0x76, 0x71, 0x6b, 0x67, 0x65, 0x63, 0x63, 0x64, 
	0x65, 0x67, 0x69, 0x6b, 0x6e, 0x70, 0x74, 0x78, 0x7b, 0x7e, 0x7e, 0x7e, 0x7e, 0x7e, 0x7e, 0x7e, 
	0x80, 0x80, 0x80, 0x80, 0x80, 0x80, 0x80, 0x80, 0x80, 0x80, 0x80, 0x80, 0x80, 0x80, 0x80, 0x80, 
	0x80, 0x80, 0x80, 0x80, 0x80, 0x80, 0x80, 0x80, 0x80, 0x80, 0x80, 0x80, 0x80, 0x80, 0x80, 0x80, 
	0x80, 0x80, 0x80, 0x80, 0x80, 0x80, 0x80, 0x80, 0x80, 0x80, 0x80, 0x80, 0x80, 0x80, 0x80, 0x80, 
	0x80, 0x80, 0x80, 0x80, 0x80, 0x80, 0x80, 0x80, 0x80, 0x80, 0x80, 0x80, 0x80, 0x80, 0x80, 0x80, 
	0x80, 0x80, 0x80, 0x80, 0x80, 0x80, 0x80, 0x80, 0x80, 0x80, 0x7f, 0x71, 0x64, 0x6a, 0x79, 0x80, 
	0x80, 0x80, 0x80, 0x80, 0x80, 0x80, 0x80, 0x80, 0x80, 0x80, 0x80, 0x80, 0x80, 0x80, 0x80, 0x80, 
	0x80, 0x80, 0x80, 0x80, 0x80, 0x80, 0x80, 0x80, 0x80, 0x7f, 0x57, 0x2, 0xf0, 0xf3, 0x19, 0x67, 
	0x7f, 0x80, 0x80, 0x80, 0x80, 0x80, 0x80, 0x80, 0x80, 0x80, 0x80, 0x80, 0x80, 0x80, 0x80, 0x80, 
	0x80, 0x80, 0x80, 0x80, 0x80, 0x80, 0x80, 0x80, 0x80, 0x78, 0x10, 0xd9, 0xdd, 0xe4, 0xd5, 0xf7, 
	0x5d, 0x7f, 0x80, 0x80, 0x80, 0x80, 0x80, 0x80, 0x80, 0x80, 0x80, 0x80, 0x80, 0x80, 0x80, 0x80, 
	0x80, 0x80, 0x80, 0x80, 0x80, 0x80, 0x80, 0x80, 0x80, 0x77, 0xf, 0xe1, 0xde, 0xe3, 0xd8, 0xce, 
	0xfc, 0x71, 0x7f, 0x80, 0x80, 0x80, 0x80, 0x80, 0x80, 0x80, 0x80, 0x80, 0x80, 0x80, 0x80, 0x80, 
	0x80, 0x80, 0x80, 0x80, 0x80, 0x80, 0x80, 0x80, 0x80, 0x80, 0x67, 0x23, 0xf5, 0xec, 0xfe, 0xb, 
	0x10, 0x1f, 0x70, 0x80, 0x80, 0x80, 0x80, 0x80, 0x80, 0x80, 0x80, 0x80, 0x80, 0x80, 0x80, 0x80, 
	0x80, 0x80, 0x80, 0x80, 0x80, 0x80, 0x80, 0x80, 0x80, 0x80, 0x80, 0x7d, 0x6e, 0x6a, 0x75, 0x7b, 
	0x72, 0x18, 0x74, 0x80, 0x80, 0x80, 0x80, 0x80, 0x80, 0x80, 0x80, 0x80, 0x80, 0x80, 0x80, 0x80, 
	0x80, 0x80, 0x80, 0x80, 0x80, 0x80, 0x80, 0x80, 0x80, 0x7d, 0x77, 0x70, 0x5e, 0x50, 0x52, 0x4f, 
	0x49, 0x21, 0x6c, 0x7d, 0x80, 0x80, 0x80, 0x80, 0x80, 0x80, 0x80, 0x80, 0x80, 0x80, 0x80, 0x80, 
	0x80, 0x80, 0x80, 0x80, 0x80, 0x80, 0x80, 0x7f, 0x6f, 0x55, 0x41, 0x3c, 0x42, 0x32, 0x15, 0x8, 
	0x4, 0xfb, 0x28, 0x58, 0x77, 0x7e, 0x7f, 0x7f, 0x80, 0x80, 0x80, 0x80, 0x80, 0x80, 0x80, 0x80, 
	0x80, 0x80, 0x80, 0x80, 0x80, 0x80, 0x7e, 0x5d, 0x2d, 0x22, 0x1c, 0x20, 0x29, 0x3a, 0x1f, 0x8, 
	0xe9, 0xe4, 0xa, 0x37, 0x4e, 0x56, 0x60, 0x75, 0x80, 0x80, 0x80, 0x80, 0x80, 0x80, 0x80, 0x80, 
	0x80, 0x80, 0x80, 0x80, 0x80, 0x80, 0x6d, 0x29, 0x15, 0x1e, 0x19, 0x9, 0x1, 0xc, 0x16, 0x1a, 
	0xb, 0x5, 0x1e, 0x33, 0x2e, 0x31, 0x3a, 0x50, 0x74, 0x80, 0x80, 0x80, 0x80, 0x80, 0x80, 0x80, 
	0x80, 0x80, 0x80, 0x80, 0x80, 0x7b, 0x44, 0xd, 0x7, 0x1b, 0x25, 0x1, 0xf1, 0xee, 0xfc, 0xf, 
	0x10, 0x14, 0x21, 0x21, 0x24, 0x28, 0x30, 0x3a, 0x4e, 0x76, 0x80, 0x80, 0x80, 0x80, 0x80, 0x80, 
	0x80, 0x80, 0x80, 0x80, 0x80, 0x69, 0x1a, 0xf8, 0xf5, 0xfe, 0x7, 0xfa, 0xf0, 0xf0, 0xfe, 0xf, 
	0xc, 0xa, 0xd, 0x14, 0x29, 0x29, 0x24, 0x29, 0x3a, 0x58, 0x7e, 0x80, 0x80, 0x80, 0x80, 0x80, 
	0x80, 0x80, 0x80, 0x80, 0x7f, 0x4c, 0xfe, 0xea, 0xe4, 0xe3, 0xe8, 0xe6, 0xe2, 0xe7, 0xfa, 0x2, 
	0xff, 0x1, 0xff, 0x11, 0x2a, 0x22, 0x1b, 0x19, 0x2a, 0x39, 0x6e, 0x80, 0x80, 0x80, 0x80, 0x80, 
	0x80, 0x80, 0x80, 0x80, 0x7b, 0x32, 0xee, 0xe1, 0xdb, 0xd8, 0xd9, 0xd9, 0xdb, 0xe3, 0xe5, 0xe7, 
	0xee, 0xf4, 0xf4, 0x14, 0x25, 0x19, 0x12, 0xf, 0x1f, 0x29, 0x5a, 0x80, 0x80, 0x80, 0x80, 0x80, 
	0x80, 0x80, 0x80, 0x80, 0x77, 0x1c, 0xe3, 0xdb, 0xd9, 0xd4, 0xd1, 0xd6, 0xdc, 0xd6, 0xcd, 0xcf, 
	0xe0, 0xe6, 0xe8, 0xa, 0x1a, 0xc, 0xb, 0x9, 0x15, 0x1f, 0x49, 0x80, 0x80, 0x80, 0x80, 0x80, 
	0x80, 0x80, 0x80, 0x80, 0x6f, 0x10, 0xdd, 0xd4, 0xcf, 0xd2, 0xd0, 0xd3, 0xd6, 0xc9, 0xc4, 0xc3, 
	0xcc, 0xda, 0xdd, 0xf9, 0xb, 0x3, 0x7, 0x6, 0xc, 0x16, 0x45, 0x7f, 0x80, 0x80, 0x80, 0x80, 
	0x80, 0x80, 0x80, 0x80, 0x71, 0x16, 0xdf, 0xd2, 0xd0, 0xd5, 0xd9, 0xd9, 0xd9, 0xcf, 0xc2, 0xbf, 
	0xc8, 0xd2, 0xd4, 0xe4, 0xf7, 0xfb, 0x1, 0x2, 0x6, 0xe, 0x4c, 0x7f, 0x80, 0x80, 0x80, 0x80, 
	0x80, 0x80, 0x80, 0x80, 0x7b, 0x2a, 0xe9, 0xd9, 0xd9, 0xd9, 0xd9, 0xd9, 0xd9, 0xd4, 0xce, 0xc9, 
	0xc6, 0xc9, 0xce, 0xda, 0xe4, 0xec, 0xf4, 0xf9, 0x0, 0x15, 0x5d, 0x80, 0x80, 0x80, 0x80, 0x80, 
	0x80, 0x80, 0x80, 0x81, 0x80, 0x42, 0xf7, 0xe3, 0xdb, 0xd9, 0xd7, 0xd7, 0xd6, 0xd4, 0xd2, 0xd0, 
	0xd2, 0xcf, 0xd4, 0xdc, 0xde, 0xe2, 0xed, 0xef, 0x1, 0x29, 0x6d, 0x80, 0x80, 0x80, 0x80, 0x80, 
	0x80, 0x80, 0x80, 0x81, 0x81, 0x5b, 0x0, 0xe3, 0xdb, 0xda, 0xd9, 0xd9, 0xd4, 0xd7, 0xd6, 0xd4, 
	0xd4, 0xd3, 0xd5, 0xdb, 0xe0, 0xe7, 0xec, 0xee, 0x9, 0x37, 0x78, 0x80, 0x80, 0x80, 0x80, 0x80, 
	0x80, 0x80, 0x80, 0x81, 0x82, 0x71, 0x1a, 0xeb, 0xdd, 0xd9, 0xd9, 0xd8, 0xd5, 0xd6, 0xd6, 0xd4, 
	0xd4, 0xd3, 0xd7, 0xdb, 0xdf, 0xe3, 0xe6, 0xed, 0x11, 0x51, 0x7e, 0x80, 0x80, 0x80, 0x80, 0x80, 
	0x80, 0x80, 0x80, 0x81, 0x82, 0x7f, 0x38, 0xf1, 0xdf, 0xd9, 0xd8, 0xd6, 0xd3, 0xd3, 0xd5, 0xd6, 
	0xd2, 0xd3, 0xd7, 0xd9, 0xdc, 0xe0, 0xe5, 0xf0, 0x2a, 0x6e, 0x80, 0x80, 0x80, 0x80, 0x80, 0x80, 
	0x80, 0x80, 0x80, 0x81, 0x82, 0x82, 0x60, 0x1, 0xe1, 0xd9, 0xd8, 0xd6, 0xd6, 0xd3, 0xd3, 0xd2, 
	0xd1, 0xd2, 0xd5, 0xd8, 0xda, 0xdf, 0xe5, 0x4, 0x52, 0x7e, 0x80, 0x80, 0x80, 0x80, 0x80, 0x80, 
	0x80, 0x80, 0x80, 0x81, 0x81, 0x81, 0x7b, 0x29, 0xe4, 0xda, 0xd7, 0xd4, 0xd3, 0xd4, 0xd2, 0xd0, 
	0xcf, 0xd1, 0xd3, 0xd5, 0xdb, 0xde, 0xee, 0x31, 0x75, 0x80, 0x80, 0x80, 0x80, 0x80, 0x80, 0x80, 
	0x80, 0x80, 0x80, 0x81, 0x81, 0x81, 0x82, 0x62, 0xfc, 0xd9, 0xd7, 0xd2, 0xd0, 0xd0, 0xcf, 0xce, 
	0xcd, 0xce, 0xd2, 0xd7, 0xda, 0xe1, 0x14, 0x67, 0x80, 0x80, 0x80, 0x80, 0x80, 0x80, 0x80, 0x80, 
	0x80, 0x80, 0x80, 0x80, 0x80, 0x81, 0x80, 0x7a, 0x40, 0xe7, 0xd4, 0xcf, 0xcd, 0xcc, 0xc9, 0xc8, 
	0xca, 0xcc, 0xcf, 0xd6, 0xd9, 0xfa, 0x53, 0x7a, 0x7f, 0x81, 0x80, 0x80, 0x80, 0x80, 0x80, 0x80, 
	0x80, 0x80, 0x80, 0x80, 0x80, 0x81, 0x7b, 0x73, 0x6b, 0x32, 0xe5, 0xcd, 0xc9, 0xc6, 0xc5, 0xc5, 
	0xc5, 0xc9, 0xce, 0xd8, 0xf7, 0x44, 0x6e, 0x74, 0x7b, 0x81, 0x81, 0x80, 0x80, 0x80, 0x80, 0x80, 
	0x80, 0x80, 0x80, 0x80, 0x7f, 0x7b, 0x74, 0x6d, 0x64, 0x52, 0x1d, 0xdb, 0xca, 0xc7, 0xc8, 0xc9, 
	0xcc, 0xd2, 0xe0, 0xfc, 0x30, 0x59, 0x69, 0x72, 0x7a, 0x80, 0x81, 0x80, 0x80, 0x80, 0x80, 0x80, 
	0x80, 0x80, 0x80, 0x81, 0x80, 0x7d, 0x79, 0x76, 0x6e, 0x60, 0x46, 0x31, 0x26, 0x1f, 0x1f, 0x21, 
	0x28, 0x32, 0x40, 0x4e, 0x5a, 0x65, 0x6f, 0x78, 0x7e, 0x81, 0x81, 0x80, 0x80, 0x80, 0x80, 0x80, 
	0x80, 0x80, 0x80, 0x80, 0x81, 0x81, 0x81, 0x80, 0x7e, 0x78, 0x73, 0x6f, 0x6e, 0x6c, 0x6c, 0x6d, 
	0x6e, 0x6f, 0x71, 0x73, 0x76, 0x78, 0x7c, 0x80, 0x80, 0x80, 0x80, 0x80, 0x80, 0x80, 0x80, 0x80, 
};
```
